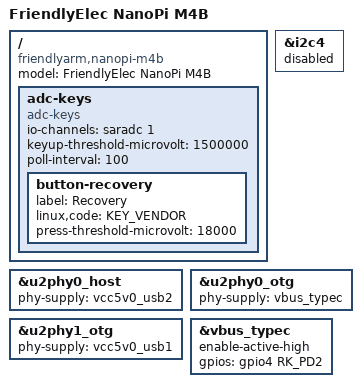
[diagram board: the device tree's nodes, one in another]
// SPDX-License-Identifier: (GPL-2.0+ OR MIT)
/*
 * FriendlyElec NanoPi M4B board device tree source
 *
 * Copyright (c) 2020 Chen-Yu Tsai <wens@csie.org>
 */

/dts-v1/;

#include "rk3399-nanopi-m4.dtsi"

/ {
	model = "FriendlyElec NanoPi M4B";
	compatible = "friendlyarm,nanopi-m4b", "rockchip,rk3399";

	adc-keys {
		compatible = "adc-keys";
		io-channels = <&saradc 1>;
		io-channel-names = "buttons";
		keyup-threshold-microvolt = <1500000>;
		poll-interval = <100>;

		button-recovery {
			label = "Recovery";
			linux,code = <KEY_VENDOR>;
			press-threshold-microvolt = <18000>;
		};
	};
};

/* No USB type-C PD power manager */
/delete-node/ &fusb0;

&i2c4 {
	status = "disabled";
};

&u2phy0_host {
	phy-supply = <&vcc5v0_usb2>;
};

&u2phy0_otg {
	phy-supply = <&vbus_typec>;
};

&u2phy1_otg {
	phy-supply = <&vcc5v0_usb1>;
};

&vbus_typec {
	enable-active-high;
	gpios = <&gpio4 RK_PD2 GPIO_ACTIVE_HIGH>;
};
